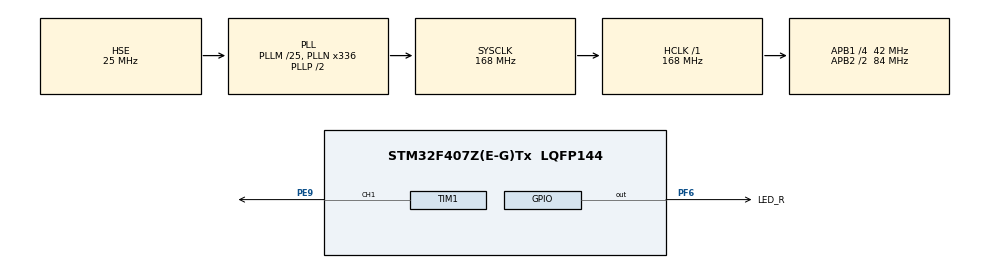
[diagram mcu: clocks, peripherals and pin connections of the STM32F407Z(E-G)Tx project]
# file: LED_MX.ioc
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Dma.Request0=TIM1_CH1
Dma.TIM1_CH1.0.Direction=DMA_MEMORY_TO_PERIPH
Dma.TIM1_CH1.0.FIFOMode=DMA_FIFOMODE_DISABLE
Dma.TIM1_CH1.0.Instance=DMA2_Stream1
Dma.TIM1_CH1.0.MemDataAlignment=DMA_MDATAALIGN_WORD
Dma.TIM1_CH1.0.MemInc=DMA_MINC_ENABLE
Dma.TIM1_CH1.0.Mode=DMA_NORMAL
Dma.TIM1_CH1.0.PeriphDataAlignment=DMA_PDATAALIGN_WORD
Dma.TIM1_CH1.0.PeriphInc=DMA_PINC_DISABLE
Dma.TIM1_CH1.0.Priority=DMA_PRIORITY_LOW
Mcu.Family=STM32F4
Mcu.Name=STM32F407Z(E-G)Tx
Mcu.Package=LQFP144
NVIC.DMA2_Stream1_IRQn=true\:0\:0\:false\:false\:true\:false\:true\:true
NVIC.PriorityGroup=NVIC_PRIORITYGROUP_4
PA13.Mode=Serial_Wire
PA13.Signal=SYS_JTMS-SWDIO
PA14.Mode=Serial_Wire
PA14.Signal=SYS_JTCK-SWCLK
PE9.Signal=S_TIM1_CH1
PF6.GPIO_Label=LED_R
PF6.GPIO_PuPd=GPIO_PULLUP
PF6.Signal=GPIO_Output
PH0-OSC_IN.Mode=HSE-External-Clock-Source
PH0-OSC_IN.Signal=RCC_OSC_IN
PH1-OSC_OUT.Mode=HSE-External-Clock-Source
PH1-OSC_OUT.Signal=RCC_OSC_OUT
ProjectManager.HeapSize=0x200
ProjectManager.StackSize=0x400
ProjectManager.TargetToolchain=STM32CubeIDE
RCC.48MHZClocksFreq_Value=84000000
RCC.AHBFreq_Value=168000000
RCC.APB1CLKDivider=RCC_HCLK_DIV4
RCC.APB1Freq_Value=42000000
RCC.APB1TimFreq_Value=84000000
RCC.APB2CLKDivider=RCC_HCLK_DIV2
RCC.APB2Freq_Value=84000000
RCC.APB2TimFreq_Value=168000000
RCC.CortexFreq_Value=168000000
RCC.HCLKFreq_Value=168000000
RCC.HSE_VALUE=25000000
RCC.HSI_VALUE=16000000
RCC.LSE_VALUE=32768
RCC.PLLM=25
RCC.PLLN=336
RCC.PLLSourceVirtual=RCC_PLLSOURCE_HSE
RCC.SYSCLKFreq_VALUE=168000000
RCC.SYSCLKSource=RCC_SYSCLKSOURCE_PLLCLK
RCC.VCOOutputFreq_Value=336000000
SH.S_TIM1_CH1.0=TIM1_CH1,PWM Generation1 CH1
TIM1.Channel-PWM\ Generation1\ CH1=TIM_CHANNEL_1
board=custom

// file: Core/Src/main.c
/* USER CODE BEGIN Header */
/**
  ******************************************************************************
  * @file           : main.c
  * @brief          : Main program body
  ******************************************************************************
  * @attention
  *
  * Copyright (c) 2026 STMicroelectronics.
  * All rights reserved.
  *
  * This software is licensed under terms that can be found in the LICENSE file
  * in the root directory of this software component.
  * If no LICENSE file comes with this software, it is provided AS-IS.
  *
  ******************************************************************************
  */
/* USER CODE END Header */
#include "main.h"

/* USER CODE BEGIN PD */
#define WS2812_NUM_LEDS    8     /* set to your strip length */

/* TIM1 clock = 168 MHz, period = 210 ticks = 1.25 us (800 kHz) */
#define WS2812_BIT_0       67    /* 0.40 us high  -> logical 0 */
#define WS2812_BIT_1       134   /* 0.80 us high  -> logical 1 */
#define WS2812_RESET_SLOTS 60    /* 60 * 1.25 us = 75 us low = latch/reset */
#define WS2812_BUF_LEN     (WS2812_NUM_LEDS * 24 + WS2812_RESET_SLOTS)
/* USER CODE END PD */

TIM_HandleTypeDef htim1;
DMA_HandleTypeDef hdma_tim1_ch1;

/* USER CODE BEGIN PV */
/* One word per bit (PWM compare value). Reset slots at the end stay 0,
   which keeps the line low long enough for the LEDs to latch. */
static uint32_t ws2812_buf[WS2812_BUF_LEN];
static volatile uint8_t ws2812_busy = 0;
/* USER CODE END PV */

void SystemClock_Config(void);
static void MX_GPIO_Init(void);
static void MX_DMA_Init(void);
static void MX_TIM1_Init(void);

/* USER CODE BEGIN 0 */
extern TIM_HandleTypeDef htim1;  /* generated by CubeMX after you enable TIM1 */

void ws2812_set_color(uint16_t led, uint8_t r, uint8_t g, uint8_t b)
{
  if (led >= WS2812_NUM_LEDS) return;

  /* WS2812B expects GRB order, MSB first */
  uint32_t grb = ((uint32_t)g << 16) | ((uint32_t)r << 8) | b;
  uint32_t *p = &ws2812_buf[led * 24];

  for (int i = 0; i < 24; i++)
  {
    p[i] = (grb & (1UL << (23 - i))) ? WS2812_BIT_1 : WS2812_BIT_0;
  }
}

void ws2812_show(void)
{
  while (ws2812_busy) { }   /* wait for previous transfer */
  ws2812_busy = 1;
  HAL_TIM_PWM_Start_DMA(&htim1, TIM_CHANNEL_1, ws2812_buf, WS2812_BUF_LEN);
}

/* Called by HAL when the DMA transfer (whole frame) is done */
void HAL_TIM_PWM_PulseFinishedCallback(TIM_HandleTypeDef *htim)
{
  if (htim->Instance == TIM1)
  {
    HAL_TIM_PWM_Stop_DMA(&htim1, TIM_CHANNEL_1);
    ws2812_busy = 0;
  }
}
/* USER CODE END 0 */

int main(void)
{

  /* MCU Configuration--------------------------------------------------------*/

  /* Reset of all peripherals, Initializes the Flash interface and the Systick. */
  HAL_Init();

  /* Configure the system clock */
  SystemClock_Config();

  /* Initialize all configured peripherals */
  MX_GPIO_Init();
  MX_DMA_Init();
  MX_TIM1_Init();

  /* Infinite loop */
  /* USER CODE BEGIN WHILE */
  uint8_t offset = 0;
  while (1)
  {
    /* simple moving rainbow-ish demo: chase R/G/B along the strip */
    for (uint16_t i = 0; i < WS2812_NUM_LEDS; i++)
    {
      switch ((i + offset) % 3)
      {
        case 0: ws2812_set_color(i, 32, 0, 0);  break; /* red   */
        case 1: ws2812_set_color(i, 0, 32, 0);  break; /* green */
        case 2: ws2812_set_color(i, 0, 0, 32);  break; /* blue  */
      }
    }
    ws2812_show();
    offset++;

    HAL_GPIO_TogglePin(LED_R_GPIO_Port, LED_R_Pin); /* heartbeat */
    HAL_Delay(200);

    /* USER CODE END WHILE */

  }
}

void SystemClock_Config(void)
{
  RCC_OscInitTypeDef RCC_OscInitStruct = {0};
  RCC_ClkInitTypeDef RCC_ClkInitStruct = {0};

  /** Configure the main internal regulator output voltage
  */
  __HAL_RCC_PWR_CLK_ENABLE();
  __HAL_PWR_VOLTAGESCALING_CONFIG(PWR_REGULATOR_VOLTAGE_SCALE1);

  /** Initializes the RCC Oscillators according to the specified parameters
  * in the RCC_OscInitTypeDef structure.
  */
  RCC_OscInitStruct.OscillatorType = RCC_OSCILLATORTYPE_HSE;
  RCC_OscInitStruct.HSEState = RCC_HSE_BYPASS;
  RCC_OscInitStruct.PLL.PLLState = RCC_PLL_ON;
  RCC_OscInitStruct.PLL.PLLSource = RCC_PLLSOURCE_HSE;
  RCC_OscInitStruct.PLL.PLLM = 25;
  RCC_OscInitStruct.PLL.PLLN = 336;
  RCC_OscInitStruct.PLL.PLLP = RCC_PLLP_DIV2;
  RCC_OscInitStruct.PLL.PLLQ = 4;
  if (HAL_RCC_OscConfig(&RCC_OscInitStruct) != HAL_OK)
  {
    Error_Handler();
  }

  /** Initializes the CPU, AHB and APB buses clocks
  */
  RCC_ClkInitStruct.ClockType = RCC_CLOCKTYPE_HCLK|RCC_CLOCKTYPE_SYSCLK
                              |RCC_CLOCKTYPE_PCLK1|RCC_CLOCKTYPE_PCLK2;
  RCC_ClkInitStruct.SYSCLKSource = RCC_SYSCLKSOURCE_PLLCLK;
  RCC_ClkInitStruct.AHBCLKDivider = RCC_SYSCLK_DIV1;
  RCC_ClkInitStruct.APB1CLKDivider = RCC_HCLK_DIV4;
  RCC_ClkInitStruct.APB2CLKDivider = RCC_HCLK_DIV2;

  if (HAL_RCC_ClockConfig(&RCC_ClkInitStruct, FLASH_LATENCY_5) != HAL_OK)
  {
    Error_Handler();
  }
}

static void MX_TIM1_Init(void)
{

  TIM_MasterConfigTypeDef sMasterConfig = {0};
  TIM_OC_InitTypeDef sConfigOC = {0};
  TIM_BreakDeadTimeConfigTypeDef sBreakDeadTimeConfig = {0};

  htim1.Instance = TIM1;
  htim1.Init.Prescaler = 0;
  htim1.Init.CounterMode = TIM_COUNTERMODE_UP;
  htim1.Init.Period = 65535;
  htim1.Init.ClockDivision = TIM_CLOCKDIVISION_DIV1;
  htim1.Init.RepetitionCounter = 0;
  htim1.Init.AutoReloadPreload = TIM_AUTORELOAD_PRELOAD_DISABLE;
  if (HAL_TIM_PWM_Init(&htim1) != HAL_OK)
  {
    Error_Handler();
  }
  sMasterConfig.MasterOutputTrigger = TIM_TRGO_RESET;
  sMasterConfig.MasterSlaveMode = TIM_MASTERSLAVEMODE_DISABLE;
  if (HAL_TIMEx_MasterConfigSynchronization(&htim1, &sMasterConfig) != HAL_OK)
  {
    Error_Handler();
  }
  sConfigOC.OCMode = TIM_OCMODE_PWM1;
  sConfigOC.Pulse = 0;
  sConfigOC.OCPolarity = TIM_OCPOLARITY_HIGH;
  sConfigOC.OCNPolarity = TIM_OCNPOLARITY_HIGH;
  sConfigOC.OCFastMode = TIM_OCFAST_DISABLE;
  sConfigOC.OCIdleState = TIM_OCIDLESTATE_RESET;
  sConfigOC.OCNIdleState = TIM_OCNIDLESTATE_RESET;
  if (HAL_TIM_PWM_ConfigChannel(&htim1, &sConfigOC, TIM_CHANNEL_1) != HAL_OK)
  {
    Error_Handler();
  }
  sBreakDeadTimeConfig.OffStateRunMode = TIM_OSSR_DISABLE;
  sBreakDeadTimeConfig.OffStateIDLEMode = TIM_OSSI_DISABLE;
  sBreakDeadTimeConfig.LockLevel = TIM_LOCKLEVEL_OFF;
  sBreakDeadTimeConfig.DeadTime = 0;
  sBreakDeadTimeConfig.BreakState = TIM_BREAK_DISABLE;
  sBreakDeadTimeConfig.BreakPolarity = TIM_BREAKPOLARITY_HIGH;
  sBreakDeadTimeConfig.AutomaticOutput = TIM_AUTOMATICOUTPUT_DISABLE;
  if (HAL_TIMEx_ConfigBreakDeadTime(&htim1, &sBreakDeadTimeConfig) != HAL_OK)
  {
    Error_Handler();
  }
  HAL_TIM_MspPostInit(&htim1);

}

static void MX_DMA_Init(void)
{

  /* DMA controller clock enable */
  __HAL_RCC_DMA2_CLK_ENABLE();

  /* DMA interrupt init */
  /* DMA2_Stream1_IRQn interrupt configuration */
  HAL_NVIC_SetPriority(DMA2_Stream1_IRQn, 0, 0);
  HAL_NVIC_EnableIRQ(DMA2_Stream1_IRQn);

}

static void MX_GPIO_Init(void)
{
  GPIO_InitTypeDef GPIO_InitStruct = {0};

  /* GPIO Ports Clock Enable */
  __HAL_RCC_GPIOF_CLK_ENABLE();
  __HAL_RCC_GPIOH_CLK_ENABLE();
  __HAL_RCC_GPIOE_CLK_ENABLE();
  __HAL_RCC_GPIOA_CLK_ENABLE();

  /*Configure GPIO pin Output Level */
  HAL_GPIO_WritePin(LED_R_GPIO_Port, LED_R_Pin, GPIO_PIN_RESET);

  /*Configure GPIO pin : LED_R_Pin */
  GPIO_InitStruct.Pin = LED_R_Pin;
  GPIO_InitStruct.Mode = GPIO_MODE_OUTPUT_PP;
  GPIO_InitStruct.Pull = GPIO_PULLUP;
  GPIO_InitStruct.Speed = GPIO_SPEED_FREQ_LOW;
  HAL_GPIO_Init(LED_R_GPIO_Port, &GPIO_InitStruct);

}

void Error_Handler(void)
{
  __disable_irq();
  while (1)
  {
  }
}
